# ISS_PRM register map
Vendor: Texas Instruments
Peripheral module from a debugger description file (folder TDA2Px).
Registers are 32-bit, access per field, reset 0x30107 unless marked. A register's access mark holds for its fields unless they carry their own. Offsets are as the file gives them; lines under a group give offsets from that group; [hi:lo] are bit positions; {n}, {i} and the like mark numbered series; 'fields as' and 'values as' point back to an identical list; <NAME> marks a mode.

## ISS_PRM
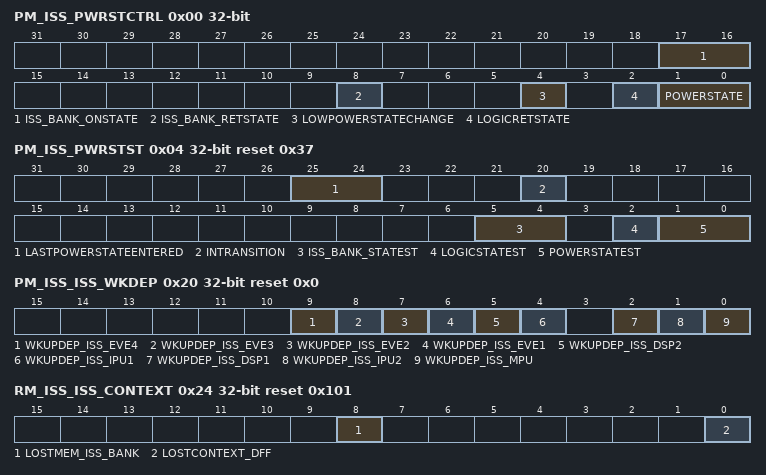
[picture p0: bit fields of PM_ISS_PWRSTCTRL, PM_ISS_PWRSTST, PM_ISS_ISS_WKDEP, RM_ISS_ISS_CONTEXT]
0x00 PM_ISS_PWRSTCTRL — This register controls the ISS power state to reach upon a domain sleep transition
  [17:16] ISS_BANK_ONSTATE ro — ISS_BANK state when domain is ON.
    3=MEM_ON (Memory bank is on when the domain is ON.)
  [8] ISS_BANK_RETSTATE rw — ISS_BANK state when domain is RETENTION.
    0=MEM_OFF (Memory bank is off when the domain is in the RETENTION state.); 1=MEM_RET (Memory bank is retained when domain is in RETENTION state.)
  [4] LOWPOWERSTATECHANGE rw — Power state change request when domain has already performed a sleep transition. Allows going into deeper low power state without waking up the power domain.
    0=DIS (Do not request a low power state change.); 1=EN (Request a low power state change. This bit is automatically cleared when the power state is effectively changed or when power state is ON.)
  [2] LOGICRETSTATE rw — Logic state when power domain is RETENTION
    0=LOGIC_OFF (Only retention registers are retained and remaing logic is off when the domain is in RETENTION state.); 1=LOGIC_RET (Whole logic is retained when domain is in RETENTION state.)
  [1:0] POWERSTATE rw — Power state control
    0=OFF (OFF state); 1=RET (RETENTION state); 2=INACT (INACTIVE state); 3=ON (ON State)
0x04 PM_ISS_PWRSTST reset 0x37 — This register provides a status on the ISS domain current power state. [warm reset insensitive]
  [25:24] LASTPOWERSTATEENTERED rw — Last low power state entered. Set to 0x3 upon write of the same only. This register is intended for debug purpose only.
    0=OFF (Power domain was previously OFF); 1=RET (Power domain was previously in RETENTION); 2=INACTIVE (Power domain was previously ON-INACTIVE); 3=ON (Power domain was previously ON-ACTIVE)
  [20] INTRANSITION ro — Domain transition status
    0=NO (No on-going transition on power domain); 1=ONGOING (Power domain transition is in progress.)
  [5:4] ISS_BANK_STATEST ro — ISS_BANK memory state status
    0=MEM_OFF (Memory is OFF); 1=MEM_RET (Memory is RETENTION); 3=MEM_ON (Memory is ON)
  [2] LOGICSTATEST ro — Logic state status
    0=OFF (Logic in domain is OFF); 1=ON (Logic in domain is ON)
  [1:0] POWERSTATEST ro — Current power state status
    0=OFF (Power domain is OFF); 1=RET (Power domain is in RETENTION); 2=INACTIVE (Power domain is ON-INACTIVE); 3=ON (Power domain is ON-ACTIVE)
0x20 PM_ISS_ISS_WKDEP reset 0x0 — This register controls wakeup dependency based on ISS service requests.
  [all] fields
    0=DISABLED (Dependency is disabled); 1=ENABLED (Dependency is enabled)
  [9] WKUPDEP_ISS_EVE4 rw — Wakeup dependency from ISS module (Swakeup signal) towards EVE4 + L3_MAIN1 + L4PER1 + L4PER2 + L4PER3 domains
  [8] WKUPDEP_ISS_EVE3 rw — Wakeup dependency from ISS module (Swakeup signal) towards EVE3 + L3_MAIN1 + L4PER1 + L4PER2 + L4PER3 domains
  [7] WKUPDEP_ISS_EVE2 rw — Wakeup dependency from ISS module (Swakeup signal) towards EVE2 + L3_MAIN1 + L4PER1 + L4PER2 + L4PER3 domains
  [6] WKUPDEP_ISS_EVE1 rw — Wakeup dependency from ISS module ( Swakeup signal) towards EVE1 + L3_MAIN1 + L4PER1 + L4PER2 + L4PER3 domains
  [5] WKUPDEP_ISS_DSP2 rw — Wakeup dependency from ISS module (Swakeup signal) towards DSP2 + L3_MAIN1 + L4PER1 + L4PER2 + L4PER3 domains
  [4] WKUPDEP_ISS_IPU1 rw — Wakeup dependency from ISS module (Swakeup signal) towards IPU1 + L3_MAIN1 + L4PER1 + L4PER2 + L4PER3 domains
  [2] WKUPDEP_ISS_DSP1 rw — Wakeup dependency from ISS module (Swakeup signal) towards DSP + L3MAIN1 + L4PER1 + L4PER2 + L4PER3 domains
  [1] WKUPDEP_ISS_IPU2 rw — Wakeup dependency from ISS module ( Swakeup signal) towards IPU2 + L3_MAIN1 + L4PER1 + L4PER2 + L4PER3 domains
  [0] WKUPDEP_ISS_MPU rw — Wakeup dependency from ISS module (Swakeup signal) towards MPU + L3_MAIN1 + L4PER1 + L4PER2 + L4PER3 domains
0x24 RM_ISS_ISS_CONTEXT reset 0x101 — This register contains dedicated ISS context statuses. [warm reset insensitive]
  [8] LOSTMEM_ISS_BANK rw — Specify if memory-based context in ISS memory bank has been lost due to a previous power transition or other reset source.
    0=MAINTAINED (Context has been maintained); 1=LOST (Context has been lost)
  [0] LOSTCONTEXT_DFF rw — Specify if DFF-based context has been lost due to a previous power transition or other reset source. (set upon assertion of ISS_RST signal)
    values as LOSTMEM_ISS_BANK
